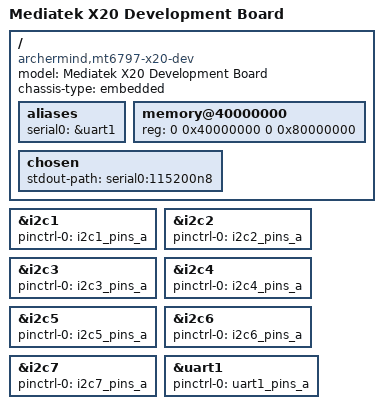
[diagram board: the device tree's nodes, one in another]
/dts-v1/;
#include "mt6797.dtsi"
/ {
	model = "Mediatek X20 Development Board";
	chassis-type = "embedded";
	compatible = "archermind,mt6797-x20-dev", "mediatek,mt6797";
	aliases {
		serial0 = &uart1;
	};
	memory@40000000 {
		device_type = "memory";
		reg = <0 0x40000000 0 0x80000000>;
	};
	chosen {
		stdout-path = "serial0:115200n8";
	};
};
&i2c1 {
	pinctrl-names = "default";
	pinctrl-0 = <&i2c1_pins_a>;
	status = "okay";
};
&i2c2 {
	pinctrl-names = "default";
	pinctrl-0 = <&i2c2_pins_a>;
	status = "okay";
};
&i2c3 {
	pinctrl-names = "default";
	pinctrl-0 = <&i2c3_pins_a>;
	status = "okay";
};
&i2c4 {
	pinctrl-names = "default";
	pinctrl-0 = <&i2c4_pins_a>;
	status = "okay";
};
&i2c5 {
	pinctrl-names = "default";
	pinctrl-0 = <&i2c5_pins_a>;
	status = "okay";
};
&i2c6 {
	pinctrl-names = "default";
	pinctrl-0 = <&i2c6_pins_a>;
	status = "okay";
};
&i2c7 {
	pinctrl-names = "default";
	pinctrl-0 = <&i2c7_pins_a>;
	status = "okay";
};
&uart1 {
	status = "okay";
	pinctrl-names = "default";
	pinctrl-0 = <&uart1_pins_a>;
};
